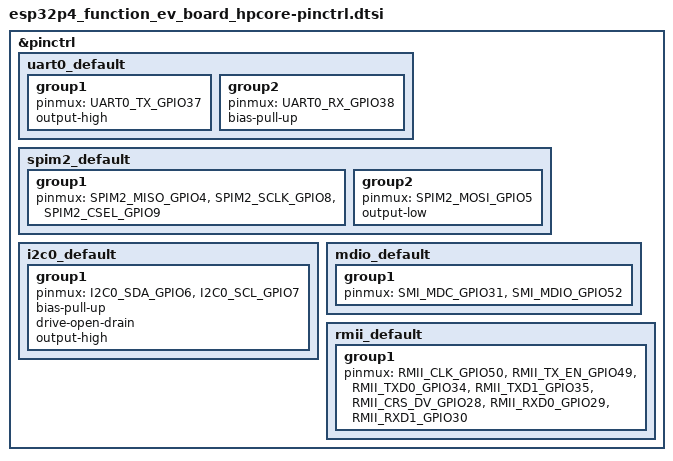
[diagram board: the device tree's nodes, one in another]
/*
 * Copyright (c) 2026 Espressif Systems (Shanghai) Co., Ltd.
 *
 * SPDX-License-Identifier: Apache-2.0
 */

#include <zephyr/dt-bindings/pinctrl/esp-pinctrl-common.h>
#include <zephyr/dt-bindings/pinctrl/esp32p4-pinctrl.h>
#include <zephyr/dt-bindings/pinctrl/esp32p4-gpio-sigmap.h>

&pinctrl {
	uart0_default: uart0_default {
		group1 {
			pinmux = <UART0_TX_GPIO37>;
			output-high;
		};

		group2 {
			pinmux = <UART0_RX_GPIO38>;
			bias-pull-up;
		};
	};

	spim2_default: spim2_default {
		group1 {
			pinmux = <SPIM2_MISO_GPIO4>,
				 <SPIM2_SCLK_GPIO8>,
				 <SPIM2_CSEL_GPIO9>;
		};

		group2 {
			pinmux = <SPIM2_MOSI_GPIO5>;
			output-low;
		};
	};

	i2c0_default: i2c0_default {
		group1 {
			pinmux = <I2C0_SDA_GPIO6>,
				 <I2C0_SCL_GPIO7>;
			bias-pull-up;
			drive-open-drain;
			output-high;
		};
	};

	mdio_default: mdio_default {
		group1 {
			pinmux = <SMI_MDC_GPIO31>,
				 <SMI_MDIO_GPIO52>;
		};
	};

	rmii_default: rmii_default {
		group1 {
			pinmux = <RMII_CLK_GPIO50>,
				 <RMII_TX_EN_GPIO49>,
				 <RMII_TXD0_GPIO34>,
				 <RMII_TXD1_GPIO35>,
				 <RMII_CRS_DV_GPIO28>,
				 <RMII_RXD0_GPIO29>,
				 <RMII_RXD1_GPIO30>;
		};
	};
};
